# CLK3_FLAGMUX_STATCOLL register map
Vendor: Texas Instruments
Peripheral module from a debugger description file (folder DRA74xP_75xP_76xP_77xP).
Registers are 32-bit, read-only, reset 0x3A0001 unless marked. A register's access mark holds for its fields unless they carry their own. Offsets are as the file gives them; lines under a group give offsets from that group; [hi:lo] are bit positions; {n}, {i} and the like mark numbered series; 'fields as' and 'values as' point back to an identical list; <NAME> marks a mode.

## CLK3_FLAGMUX_STATCOLL
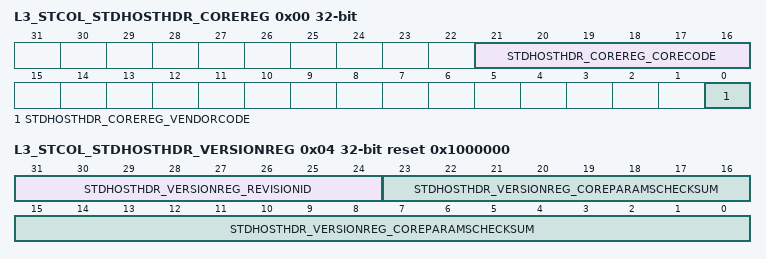
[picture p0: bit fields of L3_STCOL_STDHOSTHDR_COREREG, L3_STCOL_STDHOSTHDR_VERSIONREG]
0x00 L3_STCOL_STDHOSTHDR_COREREG access not given
  [21:16] STDHOSTHDR_COREREG_CORECODE ro — The Core Code field is a constant reporting a vendor-specific core generator code. Type: Constant. Reset value: 0x3A. (When the instance is CLK3_FLAGMUX_STATCOLL reset value is 0x37)
  [0] STDHOSTHDR_COREREG_VENDORCODE — The Vendor Code field is a constant reporting the core generator vendor code. Type: Constant. Reset value: 0x1. (access R1)
    0=Third-party_vendor; 1=STDHOSTHDR_COREREG_VENDORCODE_1_r
0x04 L3_STCOL_STDHOSTHDR_VERSIONREG reset 0x1000000
  [31:24] STDHOSTHDR_VERSIONREG_REVISIONID — The Revision Identifier field is a constant reporting the core generator revision number. Type: Constant. Reset value: 0x1.
  [23:0] STDHOSTHDR_VERSIONREG_COREPARAMSCHECKSUM — Reserved. Type: Reserved. Reset value: Reserved.
0x08 L3_STCOL_MASK0 access per field reset 0x3FF
  [9:0] MASK0 rw — mask flag inputs 0 Type: Control. Reset value: 0x7.
0x0C L3_STCOL_REGERR0 reset 0x0
  [9:0] REGERR0 — flag inputs 0 Type: Status. Reset value: X.
